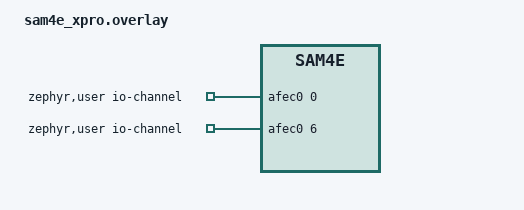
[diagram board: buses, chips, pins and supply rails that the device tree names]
/*
 * SPDX-License-Identifier: Apache-2.0
 *
 * Copyright (c) 2023, Gerson Fernando Budke
 */

/ {
	zephyr,user {
		/* adjust channel number according to pinmux in board.dts */
		io-channels = <&afec0 0>, <&afec0 6>;
	};
};

&afec0 {
	#address-cells = <1>;
	#size-cells = <0>;

	channel@0 {
		reg = <0>;
		zephyr,gain = "ADC_GAIN_1";
		zephyr,reference = "ADC_REF_INTERNAL";
		zephyr,acquisition-time = <ADC_ACQ_TIME_DEFAULT>;
		zephyr,resolution = <12>;
	};

	channel@6 {
		reg = <6>;
		zephyr,gain = "ADC_GAIN_1";
		zephyr,reference = "ADC_REF_INTERNAL";
		zephyr,acquisition-time = <ADC_ACQ_TIME_DEFAULT>;
		zephyr,resolution = <12>;
	};
};
